# ATSAMRH71F20B register map
Vendor: Microchip Technology; Series: SAMRH71; File version: 0
CPU: CM7 r1p1, little endian, MPU, FPU, 3 interrupt priority bits
Registers are 32-bit, read-write, reset 0x0 unless marked. A register's access mark holds for its fields unless they carry their own. Offsets are from the block's base; [hi:lo] are bit positions; lines under a group give offsets from that group; {n}, {i} and the like mark numbered series; 'fields as' and 'values as' point back to an identical list.

## PIO — Parallel Input/Output Controller
Base 0x40008000; register names take the prefix PIO_
{0x0+0x40*i} PIO_GROUP[{i}] (i=0..6) group
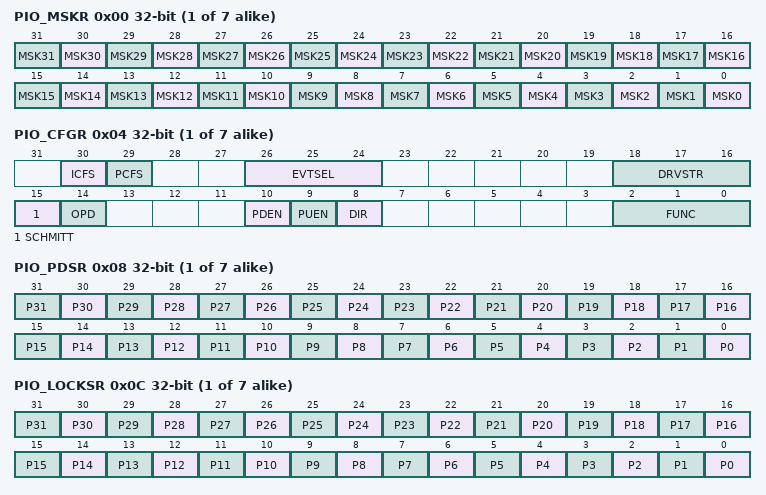
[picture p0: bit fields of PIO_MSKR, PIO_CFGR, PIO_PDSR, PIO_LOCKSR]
  0x00 PIO_MSKR — PIO Mask Register
    [all] fields
      0=DISABLED (Writing the PIO_CFGRx, PIO_ODSRx or PIO_IOFRx does not affect the corresponding I/O line configuration.); 1=ENABLED (Writing the PIO_CFGRx, PIO_ODSRx or PIO_IOFRx updates the corresponding I/O line configuration.)
    [n] MSK{n} (n=0..31) — PIO Line {n} Mask
  0x04 PIO_CFGR — PIO Configuration Register
    [30] ICFS — Interrupt Configuration Freeze Status (read-only)
      0=NOT_FROZEN (The fields are not frozen and can be written for this I/O line.); 1=FROZEN (The fields are frozen and cannot be written for this I/O line. Only a hardware reset can release these fields.)
    [29] PCFS — Physical Configuration Freeze Status (read-only)
      values as ICFS
    [26:24] EVTSEL — Event Selection
      0=FALLING (Event detection on input falling edge); 1=RISING (Event detection on input rising edge); 2=BOTH (Event detection on input both edge); 3=LOW (Event detection on low level input); 4=HIGH (Event detection on high level input)
    [18:16] DRVSTR — Drive Strength
      0=OUT_2m (Output drive is 2mA); 1=OUT_4m (Output drive is 4mA); 2=OUT_8m (Output drive is 8mA); 3=OUT_16m (Output drive is 16mA); 4=OUT_24m (Output drive is 24mA); 5=OUT_32m (Output drive is 32mA); 6=OUT_40m (Output drive is 40mA); 7=OUT_48m (Output drive is 48mA)
    [15] SCHMITT — Schmitt Trigger
      0=ENABLED (Schmitt trigger is enabled for the selected I/O lines.); 1=DISABLED (Schmitt trigger is disabled for the selected I/O lines.)
    [14] OPD — Open-Drain
      0=DISABLED (The open-drain is disabled for the selected I/O lines. I/O lines are driven at high- and low-level.); 1=ENABLED (The open-drain is enabled for the selected I/O lines. I/O lines are driven at low-level only.)
    [10] PDEN — Pull-Down Enable
      0=DISABLED (Pull-Down is disabled for the selected I/O lines.); 1=ENABLED (Pull-Down is enabled for the selected I/O lines only if PUEN is 0.)
    [9] PUEN — Pull-Up Enable
      0=DISABLED (Pull-Up is disabled for the selected I/O lines.); 1=ENABLED (Pull-Up is enabled for the selected I/O lines.)
    [8] DIR — Direction
      0=INPUT (The selected I/O lines are pure inputs.); 1=OUTPUT (The selected I/O lines are enabled in output.)
    [2:0] FUNC — I/O Line Function
      0=GPIO (Select the PIO mode for the selected I/O lines.); 1=PERIPH_A (Select the peripheral A for the selected I/O lines.); 2=PERIPH_B (Select the peripheral B for the selected I/O lines.); 3=PERIPH_C (Select the peripheral C for the selected I/O lines.); 4=PERIPH_D (Select the peripheral D for the selected I/O lines.); 5=PERIPH_E (Select the peripheral E for the selected I/O lines.); 6=PERIPH_F (Select the peripheral F for the selected I/O lines.); 7=PERIPH_G (Select the peripheral G for the selected I/O lines.)
  0x08 PIO_PDSR ro — PIO Pin Data Status Register
    [n] P{n} (n=0..31) — Input Data Status
  0x0C PIO_LOCKSR ro — PIO Lock Status Register
    [n] P{n} (n=0..31) — Lock Status
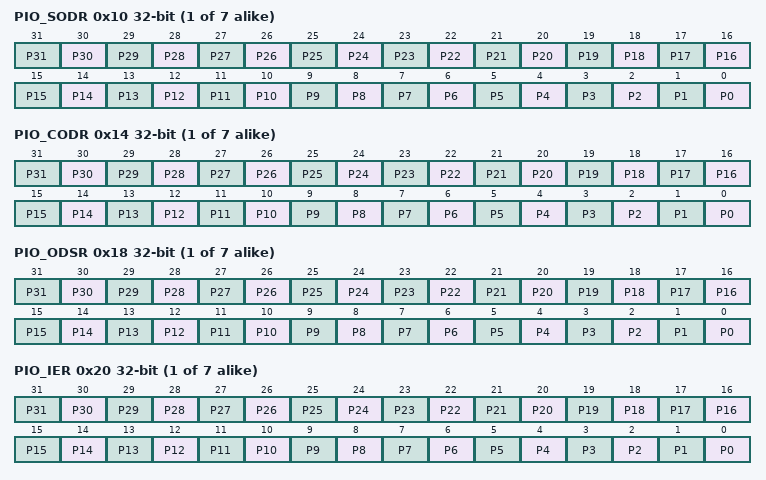
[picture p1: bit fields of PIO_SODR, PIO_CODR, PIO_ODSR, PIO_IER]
  0x10 PIO_SODR wo — PIO Set Output Data Register
    [n] P{n} (n=0..31) — Set Output Data
  0x14 PIO_CODR wo — PIO Clear Output Data Register
    [n] P{n} (n=0..31) — Clear Output Data
  0x18 PIO_ODSR — PIO Output Data Status Register
    [n] P{n} (n=0..31) — Output Data Status
  0x20 PIO_IER wo — PIO Interrupt Enable Register
    [n] P{n} (n=0..31) — Input Change Interrupt Enable
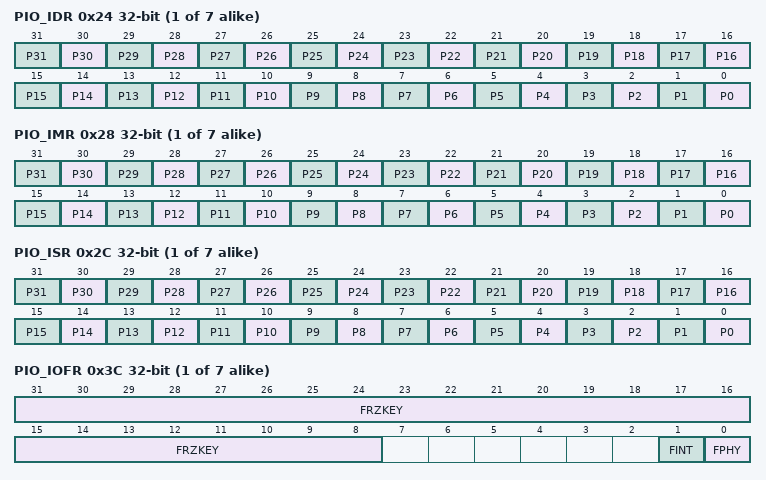
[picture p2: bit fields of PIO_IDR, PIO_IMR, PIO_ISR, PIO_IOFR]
  0x24 PIO_IDR wo — PIO Interrupt Disable Register
    [n] P{n} (n=0..31) — Input Change Interrupt Disable
  0x28 PIO_IMR ro — PIO Interrupt Mask Register
    [n] P{n} (n=0..31) — Input Change Interrupt Mask
  0x2C PIO_ISR ro — PIO Interrupt Status Register
    [n] P{n} (n=0..31) — Input Change Interrupt Status
  0x3C PIO_IOFR wo — PIO I/O Freeze Configuration Register
    [31:8] FRZKEY — Freeze Key
      0x494F46=PASSWD (Writing any other value in this field aborts the write operation of the WPEN bit.)
    [1] FINT — Freeze Interrupt Configuration
    [0] FPHY — Freeze Physical Configuration
0x500 PIO_SCDR — PIO Slow Clock Divider Debouncing Register
  [13:0] DIV — Slow Clock Divider Selection for Debouncing
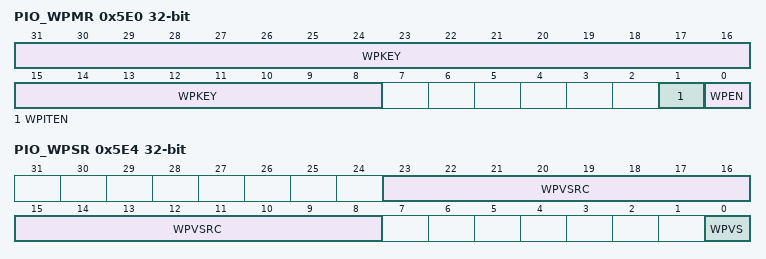
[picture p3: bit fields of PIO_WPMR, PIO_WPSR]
0x5E0 PIO_WPMR — PIO Write Protection Mode Register
  [31:8] WPKEY — Write Protection Key
    0x50494F=PASSWD (Writing any other value in this field aborts the write operation of the WPEN bit. Always reads as 0.)
  [1] WPITEN — Write Protection Interrupt Enable
  [0] WPEN — Write Protection Enable
0x5E4 PIO_WPSR ro — PIO Write Protection Status Register
  [23:8] WPVSRC — Write Protection Violation Source
  [0] WPVS — Write Protection Violation Status
